VERSION "1.0"

BU_: ECU ABS EPS Gateway

BO_ 256 EngineData: 8 ECU
 SG_ EngineSpeed : 0|16@1+ (1,0) [0|8000] "rpm" Gateway
 SG_ CoolantTemp : 16|8@1+ (1,-40) [-40|215] "degC" Gateway

BO_ 512 SteeringInfo: 8 EPS
 SG_ SteeringAngle : 0|16@1- (0.1,0) [-780|780] "deg" Gateway
 SG_ SteeringTorque : 16|8@1+ (0.5,0) [0|20] "Nm" Gateway

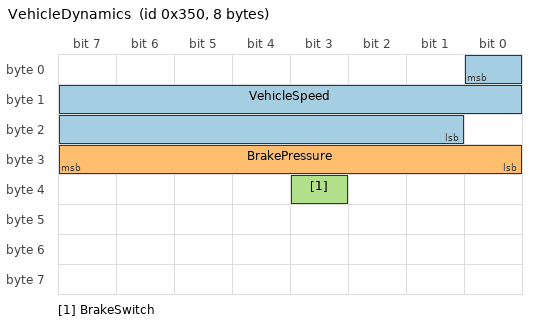
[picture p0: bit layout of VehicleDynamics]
BO_ 848 VehicleDynamics: 8 ABS
 SG_ VehicleSpeed : 0|16@0+ (0.01,0) [0|300] "km/h" Gateway
 SG_ BrakePressure : 24|8@1+ (1,0) [0|100] "%" Gateway
 SG_ BrakeSwitch : 35|1@1+ (1,0) [0|1] "" Gateway

VAL_ 848 BrakeSwitch 0 "Off" 1 "On";

CM_ SG_ 256 EngineSpeed "Engine crankshaft speed";
CM_ SG_ 256 CoolantTemp "Engine coolant temperature";
CM_ SG_ 512 SteeringAngle "Steering wheel angle, positive = right";
CM_ SG_ 512 SteeringTorque "Steering wheel torque applied";
CM_ SG_ 848 VehicleSpeed "Vehicle ground speed from ABS sensors";
CM_ SG_ 848 BrakePressure "Brake master cylinder pressure";
CM_ SG_ 848 BrakeSwitch "Brake pedal applied switch";
